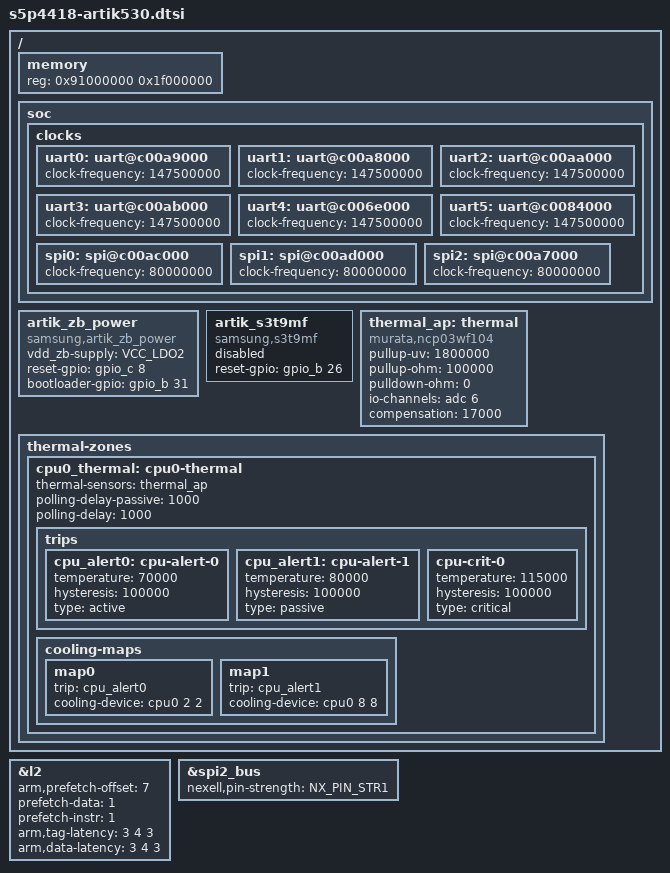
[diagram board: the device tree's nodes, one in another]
/*
 * Copyright (C) 2016  Nexell Co., Ltd.
 * Author: Youngbok, Park <ybpark@nexell.co.kr>
 *
 * This program is free software; you can redistribute it and/or
 * modify it under the terms of the GNU General Public License
 * as published by the Free Software Foundation; either version 2
 * of the License, or (at your option) any later version.
 *
 * This program is distributed in the hope that it will be useful,
 * but WITHOUT ANY WARRANTY; without even the implied warranty of
 * MERCHANTABILITY or FITNESS FOR A PARTICULAR PURPOSE.  See the
 * GNU General Public License for more details.
 *
 * You should have received a copy of the GNU General Public License
 * along with this program.  If not, see <http://www.gnu.org/licenses/>.
 */
#include <dt-bindings/interrupt-controller/irq.h>
#include "s5p4418.dtsi"

/ {
	memory {
		device_type = "memory";
		reg = <0x91000000 0x1f000000>;
	};

	soc {
		#include "s5p4418-pinctrl.dtsi"

		clocks {
			uart0:uart@c00a9000 { clock-frequency = <147500000>; };
			uart1:uart@c00a8000 { clock-frequency = <147500000>; };
			uart2:uart@c00aa000 { clock-frequency = <147500000>; };
			uart3:uart@c00ab000 { clock-frequency = <147500000>; };
			uart4:uart@c006e000 { clock-frequency = <147500000>; };
			uart5:uart@c0084000 { clock-frequency = <147500000>; };
			spi0:spi@c00ac000  { clock-frequency = <80000000>; };
			spi1:spi@c00ad000  { clock-frequency = <80000000>; };
			spi2:spi@c00a7000  { clock-frequency = <80000000>; };
		};

	};	/*** soc ***/

	artik_zb_power {
		compatible = "samsung,artik_zb_power";
		vdd_zb-supply = <&VCC_LDO2>;
		reset-gpio = <&gpio_c 8 0>;
		bootloader-gpio = <&gpio_b 31 0>;
		status = "okay";
	};

	artik_s3t9mf {
		compatible = "samsung,s3t9mf";
		reset-gpio = <&gpio_b 26 0>;
		status = "disabled";
	};

	thermal_ap:thermal {
		#thermal-sensor-cells = <0>;
		compatible = "murata,ncp03wf104";
		pullup-uv = <1800000>;   /* VCC_1.8V_AP */
		pullup-ohm = <100000>;   /* 100K */
		pulldown-ohm = <0>; /* 100K */
		io-channels = <&adc 6>;  /* AP temperature */
		compensation = <17000>; /* Compensation temp */
	};

	thermal-zones {
		cpu0_thermal: cpu0-thermal {
			thermal-sensors = <&thermal_ap>;
			polling-delay-passive = <1000>;
			polling-delay = <1000>;
			trips {
				cpu_alert0: cpu-alert-0 {
					temperature = <70000>;
					hysteresis = <100000>;
					type = "active";
				};
				cpu_alert1: cpu-alert-1 {
					temperature = <80000>;
					hysteresis = <100000>;
					type = "passive";
				};
				cpu-crit-0 {
					temperature = <115000>;
					hysteresis = <100000>;
					type = "critical";
					};
			};

			cooling-maps {
				map0 {
					trip = <&cpu_alert0>;
					cooling-device = <&cpu0 2 2>;
				};
				map1 {
					trip = <&cpu_alert1>;
					cooling-device = <&cpu0 8 8>;
				};
			};
		};
	};
};

&l2 {
	arm,prefetch-offset = <7>;
	prefetch-data = <1>;
	prefetch-instr = <1>;
	arm,tag-latency = <3 4 3>;
	arm,data-latency = <3 4 3>;
};

&spi2_bus {
	nexell,pin-strength = <NX_PIN_STR1>;
};
